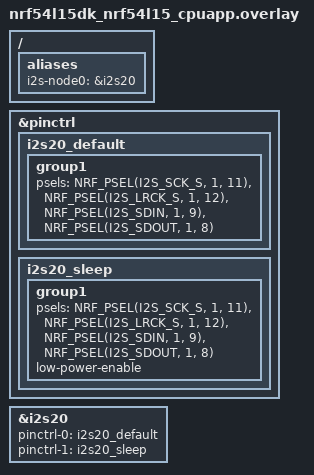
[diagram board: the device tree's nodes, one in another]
/*
 * Copyright (c) 2026 Sound Open Firmware (SOF) Project
 * SPDX-License-Identifier: Apache-2.0
 */

/ {
	aliases {
		i2s-node0 = &i2s20;
	};
};

&pinctrl {
	i2s20_default: i2s20_default {
		group1 {
			psels = <NRF_PSEL(I2S_SCK_S, 1, 11)>,
				<NRF_PSEL(I2S_LRCK_S, 1, 12)>,
				<NRF_PSEL(I2S_SDIN, 1, 9)>,
				<NRF_PSEL(I2S_SDOUT, 1, 8)>;
		};
	};

	i2s20_sleep: i2s20_sleep {
		group1 {
			psels = <NRF_PSEL(I2S_SCK_S, 1, 11)>,
				<NRF_PSEL(I2S_LRCK_S, 1, 12)>,
				<NRF_PSEL(I2S_SDIN, 1, 9)>,
				<NRF_PSEL(I2S_SDOUT, 1, 8)>;
			low-power-enable;
		};
	};
};

&i2s20 {
	status = "okay";
	pinctrl-0 = <&i2s20_default>;
	pinctrl-1 = <&i2s20_sleep>;
	pinctrl-names = "default", "sleep";
};
